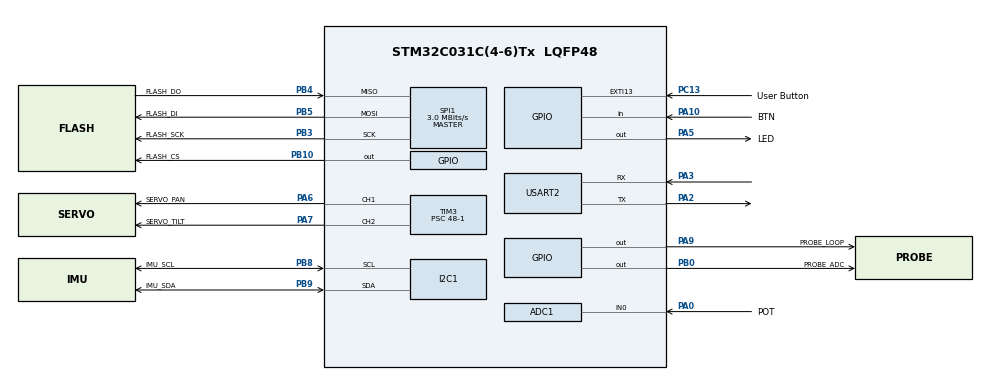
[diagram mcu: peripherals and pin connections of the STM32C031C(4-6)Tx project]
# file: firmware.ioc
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ADC1.NbrOfConversionFlag=0
ADC1.SamplingTimeCommon1=ADC_SAMPLETIME_39CYCLES_5
ADC1.SelectedChannel=ADC_CHANNEL_0
ADC1.master=1
I2C1.Timing=0x10805D88
Mcu.Family=STM32C0
Mcu.Name=STM32C031C(4-6)Tx
Mcu.Package=LQFP48
NVIC.EXTI4_15_IRQn=true\:0\:0\:false\:false\:true\:true\:true\:true
PA0.GPIO_Label=POT
PA0.Mode=IN0
PA0.Signal=ADC1_IN0
PA10.GPIO_Label=BTN
PA10.GPIO_PuPd=GPIO_PULLUP
PA10.Signal=GPIO_Input
PA13.Mode=Serial_Wire
PA13.Signal=DEBUG_SWDIO
PA14-BOOT0.Mode=Serial_Wire
PA14-BOOT0.Signal=DEBUG_SWCLK
PA2.Mode=Asynchronous
PA2.Signal=USART2_TX
PA3.Mode=Asynchronous
PA3.Signal=USART2_RX
PA5.GPIO_Label=LED
PA5.GPIO_Speed=GPIO_SPEED_FREQ_VERY_HIGH
PA5.PinState=GPIO_PIN_RESET
PA5.Signal=GPIO_Output
PA6.GPIO_Label=SERVO_PAN
PA6.Signal=S_TIM3_CH1
PA7.GPIO_Label=SERVO_TILT
PA7.Signal=S_TIM3_CH2
PA9.GPIO_Label=PROBE_LOOP
PA9.Signal=GPIO_Output
PB0.GPIO_Label=PROBE_ADC
PB0.GPIO_Speed=GPIO_SPEED_FREQ_HIGH
PB0.Signal=GPIO_Output
PB10.GPIO_Label=FLASH_CS
PB10.GPIO_Speed=GPIO_SPEED_FREQ_HIGH
PB10.PinState=GPIO_PIN_SET
PB10.Signal=GPIO_Output
PB3.GPIO_Label=FLASH_SCK
PB3.Mode=Full_Duplex_Master
PB3.Signal=SPI1_SCK
PB4.GPIO_Label=FLASH_DO
PB4.Mode=Full_Duplex_Master
PB4.Signal=SPI1_MISO
PB5.GPIO_Label=FLASH_DI
PB5.Mode=Full_Duplex_Master
PB5.Signal=SPI1_MOSI
PB8.GPIO_Label=IMU_SCL
PB8.GPIO_PuPd=GPIO_PULLUP
PB8.Mode=I2C
PB8.Signal=I2C1_SCL
PB9.GPIO_Label=IMU_SDA
PB9.GPIO_PuPd=GPIO_PULLUP
PB9.Mode=I2C
PB9.Signal=I2C1_SDA
PC13.GPIO_Label=User Button
PC13.Signal=GPXTI13
PC14-OSCX_IN\ (PC14).Mode=LSE-External-Oscillator
PC14-OSCX_IN\ (PC14).Signal=RCC_OSCX_IN
PC15-OSCX_OUT\ (PC15).Mode=LSE-External-Oscillator
PC15-OSCX_OUT\ (PC15).Signal=RCC_OSCX_OUT
PF0-OSC_IN\ (PF0).Mode=HSE-External-Oscillator
PF0-OSC_IN\ (PF0).Signal=RCC_OSC_IN
PF1-OSC_OUT\ (PF1).Mode=HSE-External-Oscillator
PF1-OSC_OUT\ (PF1).Signal=RCC_OSC_OUT
ProjectManager.HeapSize=0x200
ProjectManager.StackSize=0x400
ProjectManager.TargetToolchain=Makefile
RCC.ADCFreq_Value=48000000
RCC.AHBFreq_Value=48000000
RCC.CortexFreq_Value=48000000
RCC.EXTERNAL_CLOCK_VALUE=12288000
RCC.HCLKFreq_Value=48000000
RCC.HSE_VALUE=48000000
RCC.HSISYSCLKDivider=RCC_HSI_DIV1
RCC.HSI_VALUE=48000000
RCC.SYSCLKFreq_VALUE=48000000
SH.S_TIM3_CH1.0=TIM3_CH1,PWM Generation1 CH1
SH.S_TIM3_CH2.0=TIM3_CH2,PWM Generation2 CH2
SPI1.BaudRatePrescaler=SPI_BAUDRATEPRESCALER_16
SPI1.CLKPhase=SPI_PHASE_1EDGE
SPI1.CLKPolarity=SPI_POLARITY_LOW
SPI1.CalculateBaudRate=3.0 MBits/s
SPI1.DataSize=SPI_DATASIZE_8BIT
SPI1.Direction=SPI_DIRECTION_2LINES
SPI1.Mode=SPI_MODE_MASTER
SPI1.VirtualNSS=VM_NSSSOFT
SPI1.VirtualType=VM_MASTER
TIM3.AutoReloadPreload=TIM_AUTORELOAD_PRELOAD_ENABLE
TIM3.Channel-PWM\ Generation1\ CH1=TIM_CHANNEL_1
TIM3.Channel-PWM\ Generation2\ CH2=TIM_CHANNEL_2
TIM3.Period=20000-1
TIM3.Prescaler=48-1
TIM3.Pulse-PWM\ Generation1\ CH1=1500
TIM3.Pulse-PWM\ Generation2\ CH2=1500
USART2.VirtualMode-Asynchronous=VM_ASYNC
board=NUCLEO-C031C6

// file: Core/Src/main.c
/* USER CODE BEGIN Header */
/**
 * main.c — Core: лише ініціалізація периферії (у форматі STM32CubeMX,
 * firmware.ioc) і передача керування в App/app_main().
 *
 * Правило: увесь власний код — між USER CODE BEGIN/END, щоб повторна
 * генерація з .ioc його не стерла. Бізнес-логіки тут немає.
 *
 * MCU: STM32C031C6 (Nucleo-C031C6 / Wokwi), SYSCLK = HSI48 = 48 МГц.
 */
/* USER CODE END Header */
#include "main.h"

/* USER CODE BEGIN Includes */
#include "app.h"
/* USER CODE END Includes */

ADC_HandleTypeDef  hadc1;
I2C_HandleTypeDef  hi2c1;
SPI_HandleTypeDef  hspi1;
TIM_HandleTypeDef  htim3;
UART_HandleTypeDef huart2;

void SystemClock_Config(void);
static void MX_GPIO_Init(void);
static void MX_USART2_UART_Init(void);
static void MX_I2C1_Init(void);
static void MX_ADC1_Init(void);
static void MX_TIM3_Init(void);
static void MX_SPI1_Init(void);

int main(void)
{
  HAL_Init();
  SystemClock_Config();

  MX_GPIO_Init();
  MX_USART2_UART_Init();
  MX_I2C1_Init();
  MX_ADC1_Init();
  MX_TIM3_Init();
  MX_SPI1_Init();

  /* USER CODE BEGIN 2 */
  HAL_TIM_PWM_Start(&htim3, TIM_CHANNEL_1);
  HAL_TIM_PWM_Start(&htim3, TIM_CHANNEL_2);
  app_main();                 /* не повертається */
  /* USER CODE END 2 */

  while (1)
  {
  }
}

/* HSI48, HSIDIV = 1 -> SYSCLK = HCLK = PCLK = 48 МГц (RM0490 розд. 6, рис. «Clock tree») */
void SystemClock_Config(void)
{
  RCC_OscInitTypeDef osc = {0};
  RCC_ClkInitTypeDef clk = {0};

  osc.OscillatorType      = RCC_OSCILLATORTYPE_HSI;
  osc.HSIState            = RCC_HSI_ON;
  osc.HSIDiv              = RCC_HSI_DIV1;
  osc.HSICalibrationValue = RCC_HSICALIBRATION_DEFAULT;
  if (HAL_RCC_OscConfig(&osc) != HAL_OK) Error_Handler();

  clk.ClockType      = RCC_CLOCKTYPE_HCLK | RCC_CLOCKTYPE_SYSCLK | RCC_CLOCKTYPE_PCLK1;
  clk.SYSCLKSource   = RCC_SYSCLKSOURCE_HSI;
  clk.SYSCLKDivider  = RCC_SYSCLK_DIV1;
  clk.AHBCLKDivider  = RCC_HCLK_DIV1;
  clk.APB1CLKDivider = RCC_APB1_DIV1;
  if (HAL_RCC_ClockConfig(&clk, FLASH_LATENCY_1) != HAL_OK) Error_Handler();
}

/* USART2: BRR = 48 МГц / 115200 = 416.7 -> 417, похибка −0.08 % */
static void MX_USART2_UART_Init(void)
{
  huart2.Instance            = USART2;
  huart2.Init.BaudRate       = 115200;
  huart2.Init.WordLength     = UART_WORDLENGTH_8B;
  huart2.Init.StopBits       = UART_STOPBITS_1;
  huart2.Init.Parity         = UART_PARITY_NONE;
  huart2.Init.Mode           = UART_MODE_TX_RX;
  huart2.Init.HwFlowCtl      = UART_HWCONTROL_NONE;
  huart2.Init.OverSampling   = UART_OVERSAMPLING_16;
  huart2.Init.OneBitSampling = UART_ONE_BIT_SAMPLE_DISABLE;
  huart2.Init.ClockPrescaler = UART_PRESCALER_DIV1;
  huart2.AdvancedInit.AdvFeatureInit = UART_ADVFEATURE_NO_INIT;
  if (HAL_UART_Init(&huart2) != HAL_OK) Error_Handler();
}

/* I2C1 Standard mode 100 кГц, TIMINGR розраховано в docs/pinout.md §5 */
static void MX_I2C1_Init(void)
{
  hi2c1.Instance              = I2C1;
  hi2c1.Init.Timing           = BOARD_I2C_TIMING;
  hi2c1.Init.OwnAddress1      = 0;
  hi2c1.Init.AddressingMode   = I2C_ADDRESSINGMODE_7BIT;
  hi2c1.Init.DualAddressMode  = I2C_DUALADDRESS_DISABLE;
  hi2c1.Init.OwnAddress2      = 0;
  hi2c1.Init.OwnAddress2Masks = I2C_OA2_NOMASK;
  hi2c1.Init.GeneralCallMode  = I2C_GENERALCALL_DISABLE;
  hi2c1.Init.NoStretchMode    = I2C_NOSTRETCH_DISABLE;
  if (HAL_I2C_Init(&hi2c1) != HAL_OK) Error_Handler();
  if (HAL_I2CEx_ConfigAnalogFilter(&hi2c1, I2C_ANALOGFILTER_ENABLE) != HAL_OK) Error_Handler();
  if (HAL_I2CEx_ConfigDigitalFilter(&hi2c1, 0) != HAL_OK) Error_Handler();
}

/* ADC1: f_ADC = PCLK/2 = 24 МГц, t_conv = (39.5 + 12.5)/24 МГц = 2.17 мкс */
static void MX_ADC1_Init(void)
{
  ADC_ChannelConfTypeDef ch = {0};

  hadc1.Instance                   = ADC1;
  hadc1.Init.ClockPrescaler        = ADC_CLOCK_SYNC_PCLK_DIV2;
  hadc1.Init.Resolution            = ADC_RESOLUTION_12B;
  hadc1.Init.DataAlign             = ADC_DATAALIGN_RIGHT;
  hadc1.Init.ScanConvMode          = ADC_SCAN_DISABLE;
  hadc1.Init.EOCSelection          = ADC_EOC_SINGLE_CONV;
  hadc1.Init.LowPowerAutoWait      = DISABLE;
  hadc1.Init.LowPowerAutoPowerOff  = DISABLE;
  hadc1.Init.ContinuousConvMode    = DISABLE;
  hadc1.Init.NbrOfConversion       = 1;
  hadc1.Init.DiscontinuousConvMode = DISABLE;
  hadc1.Init.ExternalTrigConv      = ADC_SOFTWARE_START;
  hadc1.Init.ExternalTrigConvEdge  = ADC_EXTERNALTRIGCONVEDGE_NONE;
  hadc1.Init.DMAContinuousRequests = DISABLE;
  hadc1.Init.Overrun               = ADC_OVR_DATA_OVERWRITTEN;
  hadc1.Init.SamplingTimeCommon1   = ADC_SAMPLETIME_39CYCLES_5;
  hadc1.Init.OversamplingMode      = DISABLE;
  hadc1.Init.TriggerFrequencyMode  = ADC_TRIGGER_FREQ_HIGH;
  if (HAL_ADC_Init(&hadc1) != HAL_OK) Error_Handler();

  ch.Channel      = BOARD_POT_CHANNEL;
  ch.Rank         = ADC_REGULAR_RANK_1;
  ch.SamplingTime = ADC_SAMPLINGTIME_COMMON_1;
  if (HAL_ADC_ConfigChannel(&hadc1, &ch) != HAL_OK) Error_Handler();
}

/* TIM3: 48 МГц / (PSC+1 = 48) = 1 МГц; (ARR+1) = 20000 -> 50 Гц; CCR = мкс */
static void MX_TIM3_Init(void)
{
  TIM_ClockConfigTypeDef  clk = {0};
  TIM_MasterConfigTypeDef mst = {0};
  TIM_OC_InitTypeDef      oc  = {0};

  htim3.Instance               = TIM3;
  htim3.Init.Prescaler         = BOARD_SERVO_PSC;
  htim3.Init.CounterMode       = TIM_COUNTERMODE_UP;
  htim3.Init.Period            = BOARD_SERVO_ARR;
  htim3.Init.ClockDivision     = TIM_CLOCKDIVISION_DIV1;
  htim3.Init.AutoReloadPreload = TIM_AUTORELOAD_PRELOAD_ENABLE;
  if (HAL_TIM_Base_Init(&htim3) != HAL_OK) Error_Handler();
  clk.ClockSource = TIM_CLOCKSOURCE_INTERNAL;
  if (HAL_TIM_ConfigClockSource(&htim3, &clk) != HAL_OK) Error_Handler();
  if (HAL_TIM_PWM_Init(&htim3) != HAL_OK) Error_Handler();
  mst.MasterOutputTrigger = TIM_TRGO_RESET;
  mst.MasterSlaveMode     = TIM_MASTERSLAVEMODE_DISABLE;
  if (HAL_TIMEx_MasterConfigSynchronization(&htim3, &mst) != HAL_OK) Error_Handler();

  oc.OCMode     = TIM_OCMODE_PWM1;
  oc.Pulse      = 1500;
  oc.OCPolarity = TIM_OCPOLARITY_HIGH;
  oc.OCFastMode = TIM_OCFAST_DISABLE;
  if (HAL_TIM_PWM_ConfigChannel(&htim3, &oc, TIM_CHANNEL_1) != HAL_OK) Error_Handler();
  if (HAL_TIM_PWM_ConfigChannel(&htim3, &oc, TIM_CHANNEL_2) != HAL_OK) Error_Handler();
  HAL_TIM_MspPostInit(&htim3);
}

/* SPI1 master, mode 0 (CPOL=0, CPHA=0), MSB first, 8 біт,
 * SCK = 48 МГц / 16 = 3 МГц; NSS програмний (CS# = PB10, GPIO) */
static void MX_SPI1_Init(void)
{
  hspi1.Instance               = SPI1;
  hspi1.Init.Mode              = SPI_MODE_MASTER;
  hspi1.Init.Direction         = SPI_DIRECTION_2LINES;
  hspi1.Init.DataSize          = SPI_DATASIZE_8BIT;
  hspi1.Init.CLKPolarity       = SPI_POLARITY_LOW;
  hspi1.Init.CLKPhase          = SPI_PHASE_1EDGE;
  hspi1.Init.NSS               = SPI_NSS_SOFT;
  hspi1.Init.BaudRatePrescaler = BOARD_SPI_PRESC;
  hspi1.Init.FirstBit          = SPI_FIRSTBIT_MSB;
  hspi1.Init.TIMode            = SPI_TIMODE_DISABLE;
  hspi1.Init.CRCCalculation    = SPI_CRCCALCULATION_DISABLE;
  hspi1.Init.CRCPolynomial     = 7;
  hspi1.Init.CRCLength         = SPI_CRC_LENGTH_DATASIZE;
  hspi1.Init.NSSPMode          = SPI_NSS_PULSE_DISABLE;
  if (HAL_SPI_Init(&hspi1) != HAL_OK) Error_Handler();
}

static void MX_GPIO_Init(void)
{
  GPIO_InitTypeDef g = {0};

  __HAL_RCC_GPIOA_CLK_ENABLE();
  __HAL_RCC_GPIOB_CLK_ENABLE();

  /* Початкові рівні: LED off, CS# high (flash не вибрано), проби low */
  HAL_GPIO_WritePin(BOARD_LED_PORT, BOARD_LED_PIN, GPIO_PIN_RESET);
  HAL_GPIO_WritePin(BOARD_FLASH_CS_PORT, BOARD_FLASH_CS_PIN, GPIO_PIN_SET);
  HAL_GPIO_WritePin(BOARD_PROBE_ADC_PORT, BOARD_PROBE_ADC_PIN, GPIO_PIN_RESET);
  HAL_GPIO_WritePin(BOARD_PROBE_LOOP_PORT, BOARD_PROBE_LOOP_PIN, GPIO_PIN_RESET);

  g.Mode  = GPIO_MODE_OUTPUT_PP;
  g.Pull  = GPIO_NOPULL;
  g.Speed = GPIO_SPEED_FREQ_LOW;
  g.Pin   = BOARD_LED_PIN;          HAL_GPIO_Init(BOARD_LED_PORT, &g);
  g.Pin   = BOARD_PROBE_LOOP_PIN;   HAL_GPIO_Init(BOARD_PROBE_LOOP_PORT, &g);
  g.Speed = GPIO_SPEED_FREQ_HIGH;   /* CS# і проба ADC — фронти мають бути чіткими на LA */
  g.Pin   = BOARD_FLASH_CS_PIN;     HAL_GPIO_Init(BOARD_FLASH_CS_PORT, &g);
  g.Pin   = BOARD_PROBE_ADC_PIN;    HAL_GPIO_Init(BOARD_PROBE_ADC_PORT, &g);

  g.Mode  = GPIO_MODE_INPUT;
  g.Pull  = GPIO_PULLUP;
  g.Speed = GPIO_SPEED_FREQ_LOW;
  g.Pin   = BOARD_BTN_PIN;          HAL_GPIO_Init(BOARD_BTN_PORT, &g);
}

void Error_Handler(void)
{
  /* USER CODE BEGIN Error_Handler_Debug */
  __disable_irq();
  while (1) {
    HAL_GPIO_TogglePin(BOARD_LED_PORT, BOARD_LED_PIN);   /* швидке блимання LD4 */
    for (volatile uint32_t i = 0; i < 200000; i++) { }
  }
  /* USER CODE END Error_Handler_Debug */
}
